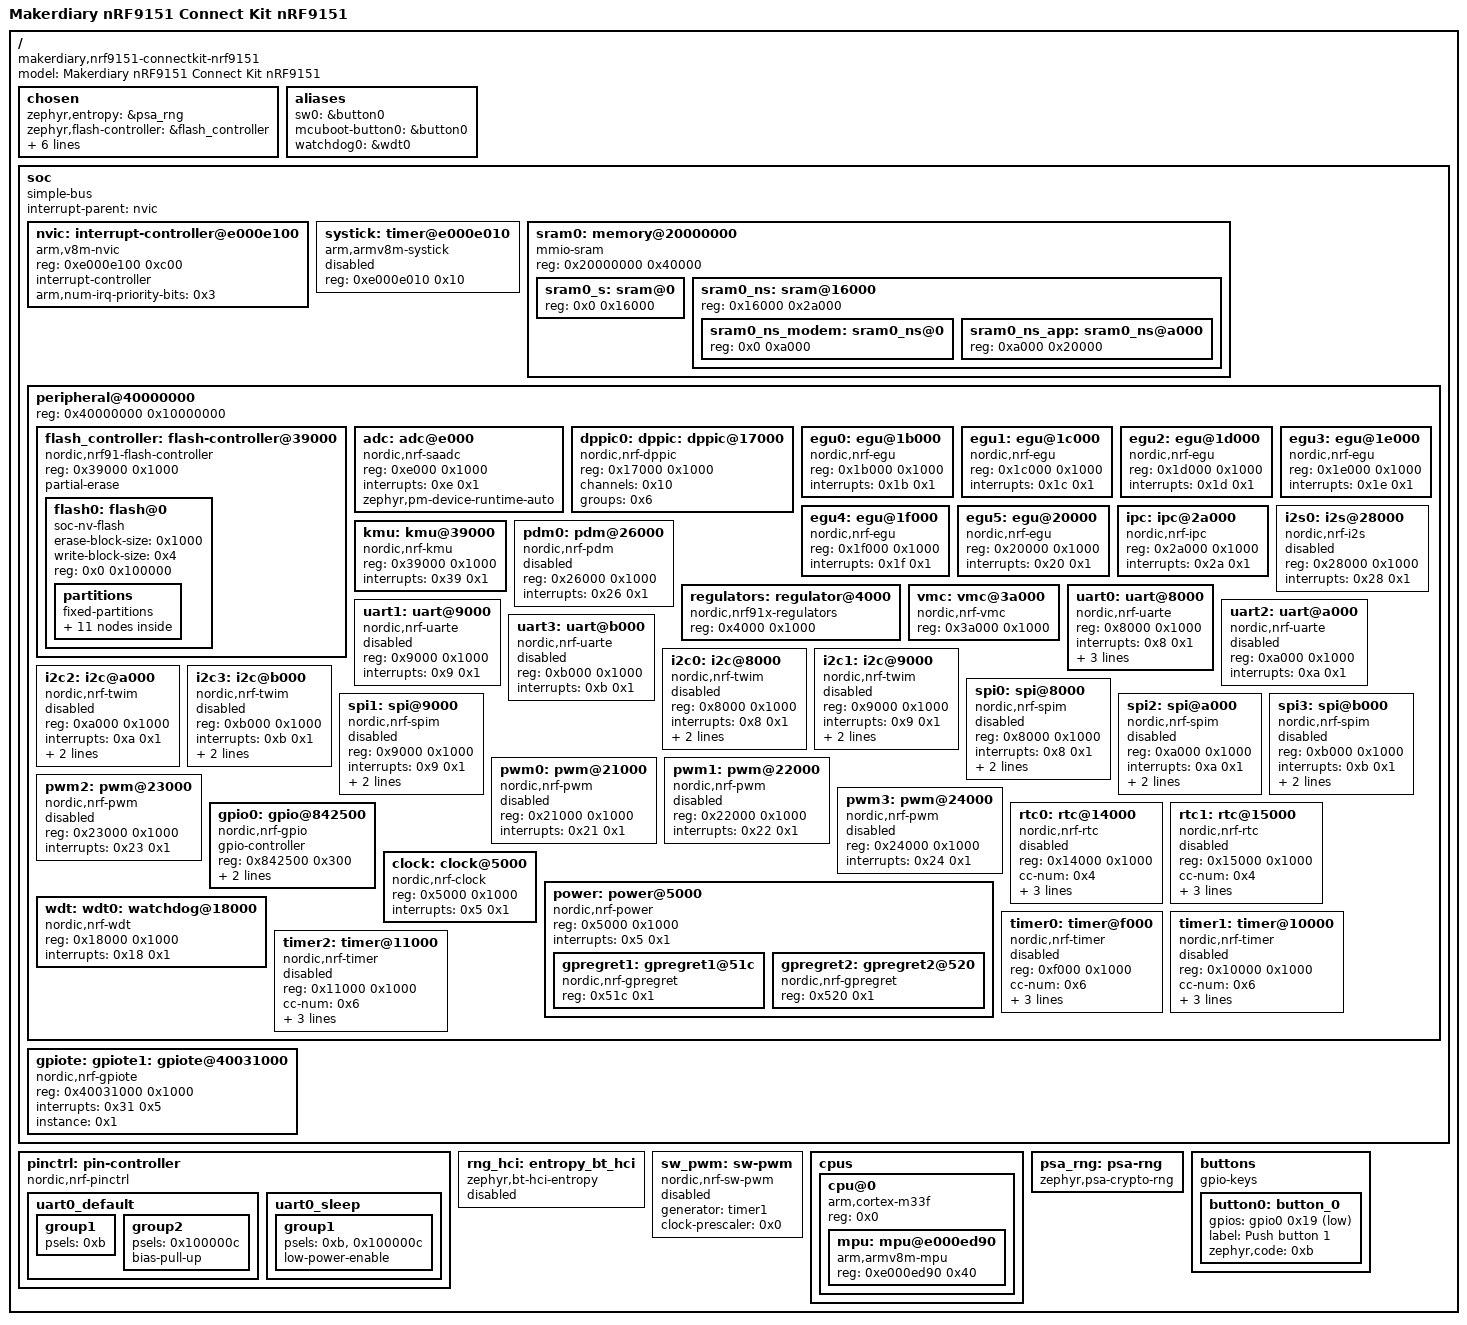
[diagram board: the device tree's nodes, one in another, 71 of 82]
/dts-v1/;

/* node '/' defined in zephyr/dts/common/skeleton.dtsi:9 */
/ {
	#address-cells = < 0x1 >;                             /* in zephyr/dts/common/skeleton.dtsi:10 */
	#size-cells = < 0x1 >;                                /* in zephyr/dts/common/skeleton.dtsi:11 */
	model = "Makerdiary nRF9151 Connect Kit nRF9151";     /* in ../../Documents/DECT_2020_GIT/dect_shell/boards/nrf9151_connectkit/nrf9151_connectkit_nrf9151_common.dtsi:10 */
	compatible = "makerdiary,nrf9151-connectkit-nrf9151"; /* in ../../Documents/DECT_2020_GIT/dect_shell/boards/nrf9151_connectkit/nrf9151_connectkit_nrf9151_common.dtsi:11 */

	/* node '/chosen' defined in zephyr/dts/common/skeleton.dtsi:13 */
	chosen {
		zephyr,entropy = &psa_rng;                   /* in zephyr/dts/arm/nordic/nrf91_ns.dtsi:31 */
		zephyr,flash-controller = &flash_controller; /* in zephyr/dts/arm/nordic/nrf91_ns.dtsi:32 */
		zephyr,console = &uart0;                     /* in ../../Documents/DECT_2020_GIT/dect_shell/boards/nrf9151_connectkit/nrf9151_connectkit_nrf9151_common.dtsi:14 */
		zephyr,shell-uart = &uart0;                  /* in ../../Documents/DECT_2020_GIT/dect_shell/boards/nrf9151_connectkit/nrf9151_connectkit_nrf9151_common.dtsi:15 */
		zephyr,uart-mcumgr = &uart0;                 /* in ../../Documents/DECT_2020_GIT/dect_shell/boards/nrf9151_connectkit/nrf9151_connectkit_nrf9151_common.dtsi:16 */
		zephyr,flash = &flash0;                      /* in ../../Documents/DECT_2020_GIT/dect_shell/boards/nrf9151_connectkit/nrf9151_connectkit_nrf9151_ns.dts:13 */
		zephyr,sram = &sram0_ns_app;                 /* in ../../Documents/DECT_2020_GIT/dect_shell/boards/nrf9151_connectkit/nrf9151_connectkit_nrf9151_ns.dts:14 */
		zephyr,code-partition = &slot0_ns_partition; /* in ../../Documents/DECT_2020_GIT/dect_shell/boards/nrf9151_connectkit/nrf9151_connectkit_nrf9151_ns.dts:15 */
	};

	/* node '/aliases' defined in zephyr/dts/common/skeleton.dtsi:15 */
	aliases {
		sw0 = &button0;             /* in ../../Documents/DECT_2020_GIT/dect_shell/boards/nrf9151_connectkit/nrf9151_connectkit_nrf9151_common.dtsi:30 */
		mcuboot-button0 = &button0; /* in ../../Documents/DECT_2020_GIT/dect_shell/boards/nrf9151_connectkit/nrf9151_connectkit_nrf9151_common.dtsi:31 */
		watchdog0 = &wdt0;          /* in ../../Documents/DECT_2020_GIT/dect_shell/boards/nrf9151_connectkit/nrf9151_connectkit_nrf9151_common.dtsi:32 */
	};

	/* node '/soc' defined in zephyr/dts/arm/armv8-m.dtsi:6 */
	soc {
		#address-cells = < 0x1 >;     /* in zephyr/dts/arm/armv8-m.dtsi:7 */
		#size-cells = < 0x1 >;        /* in zephyr/dts/arm/armv8-m.dtsi:8 */
		interrupt-parent = < &nvic >; /* in zephyr/dts/arm/armv8-m.dtsi:10 */
		ranges;                       /* in zephyr/dts/arm/armv8-m.dtsi:11 */
		compatible = "simple-bus";    /* in zephyr/dts/arm/nordic/nrf9151_ns_laca.dtsi:21 */

		/* node '/soc/interrupt-controller@e000e100' defined in zephyr/dts/arm/armv8-m.dtsi:13 */
		nvic: interrupt-controller@e000e100 {
			#address-cells = < 0x1 >;            /* in zephyr/dts/arm/armv8-m.dtsi:14 */
			compatible = "arm,v8m-nvic";         /* in zephyr/dts/arm/armv8-m.dtsi:15 */
			reg = < 0xe000e100 0xc00 >;          /* in zephyr/dts/arm/armv8-m.dtsi:16 */
			interrupt-controller;                /* in zephyr/dts/arm/armv8-m.dtsi:17 */
			#interrupt-cells = < 0x2 >;          /* in zephyr/dts/arm/armv8-m.dtsi:18 */
			arm,num-irq-priority-bits = < 0x3 >; /* in zephyr/dts/arm/nordic/nrf91_ns.dtsi:73 */
			phandle = < 0x1 >;                   /* in zephyr/dts/arm/armv8-m.dtsi:10 */
		};

		/* node '/soc/timer@e000e010' defined in zephyr/dts/arm/armv8-m.dtsi:21 */
		systick: timer@e000e010 {
			compatible = "arm,armv8m-systick"; /* in zephyr/dts/arm/armv8-m.dtsi:22 */
			reg = < 0xe000e010 0x10 >;         /* in zephyr/dts/arm/armv8-m.dtsi:23 */
			status = "disabled";               /* in zephyr/dts/arm/nordic/nrf91_ns.dtsi:78 */
		};

		/* node '/soc/memory@20000000' defined in zephyr/dts/arm/nordic/nrf91_ns.dtsi:36 */
		sram0: memory@20000000 {
			compatible = "mmio-sram";            /* in zephyr/dts/arm/nordic/nrf91_ns.dtsi:37 */
			#address-cells = < 0x1 >;            /* in zephyr/dts/arm/nordic/nrf91_ns.dtsi:38 */
			#size-cells = < 0x1 >;               /* in zephyr/dts/arm/nordic/nrf91_ns.dtsi:39 */
			reg = < 0x20000000 0x40000 >;        /* in zephyr/dts/arm/nordic/nrf9151_ns_laca.dtsi:15 */
			ranges = < 0x0 0x20000000 0x40000 >; /* in zephyr/dts/arm/nordic/nrf9151_ns_laca.dtsi:16 */

			/* node '/soc/memory@20000000/sram@0' defined in zephyr/dts/vendor/nordic/nrf91xx_partition.dtsi:107 */
			sram0_s: sram@0 {
				reg = < 0x0 0x16000 >; /* in zephyr/dts/vendor/nordic/nrf91xx_partition.dtsi:109 */
			};

			/* node '/soc/memory@20000000/sram@16000' defined in zephyr/dts/vendor/nordic/nrf91xx_partition.dtsi:112 */
			sram0_ns: sram@16000 {
				reg = < 0x16000 0x2a000 >;        /* in zephyr/dts/vendor/nordic/nrf91xx_partition.dtsi:114 */
				#address-cells = < 0x1 >;         /* in zephyr/dts/vendor/nordic/nrf91xx_partition.dtsi:115 */
				#size-cells = < 0x1 >;            /* in zephyr/dts/vendor/nordic/nrf91xx_partition.dtsi:116 */
				ranges = < 0x0 0x16000 0x2a000 >; /* in zephyr/dts/vendor/nordic/nrf91xx_partition.dtsi:117 */

				/* node '/soc/memory@20000000/sram@16000/sram0_ns@0' defined in zephyr/dts/vendor/nordic/nrf91xx_partition.dtsi:119 */
				sram0_ns_modem: sram0_ns@0 {
					reg = < 0x0 0xa000 >; /* in zephyr/dts/vendor/nordic/nrf91xx_partition.dtsi:121 */
				};

				/* node '/soc/memory@20000000/sram@16000/sram0_ns@a000' defined in zephyr/dts/vendor/nordic/nrf91xx_partition.dtsi:124 */
				sram0_ns_app: sram0_ns@a000 {
					reg = < 0xa000 0x20000 >; /* in zephyr/dts/vendor/nordic/nrf91xx_partition.dtsi:126 */
				};
			};
		};

		/* node '/soc/peripheral@40000000' defined in zephyr/dts/arm/nordic/nrf91_ns.dtsi:42 */
		peripheral@40000000 {
			#address-cells = < 0x1 >;               /* in zephyr/dts/arm/nordic/nrf91_ns.dtsi:43 */
			#size-cells = < 0x1 >;                  /* in zephyr/dts/arm/nordic/nrf91_ns.dtsi:44 */
			reg = < 0x40000000 0x10000000 >;        /* in zephyr/dts/arm/nordic/nrf91_ns.dtsi:45 */
			ranges = < 0x0 0x40000000 0x10000000 >; /* in zephyr/dts/arm/nordic/nrf91_ns.dtsi:46 */

			/* node '/soc/peripheral@40000000/flash-controller@39000' defined in zephyr/dts/arm/nordic/nrf91_peripherals.dtsi:7 */
			flash_controller: flash-controller@39000 {
				compatible = "nordic,nrf91-flash-controller"; /* in zephyr/dts/arm/nordic/nrf91_peripherals.dtsi:8 */
				reg = < 0x39000 0x1000 >;                     /* in zephyr/dts/arm/nordic/nrf91_peripherals.dtsi:9 */
				partial-erase;                                /* in zephyr/dts/arm/nordic/nrf91_peripherals.dtsi:10 */
				#address-cells = < 0x1 >;                     /* in zephyr/dts/arm/nordic/nrf91_peripherals.dtsi:12 */
				#size-cells = < 0x1 >;                        /* in zephyr/dts/arm/nordic/nrf91_peripherals.dtsi:13 */

				/* node '/soc/peripheral@40000000/flash-controller@39000/flash@0' defined in zephyr/dts/arm/nordic/nrf91_peripherals.dtsi:15 */
				flash0: flash@0 {
					compatible = "soc-nv-flash";   /* in zephyr/dts/arm/nordic/nrf91_peripherals.dtsi:16 */
					erase-block-size = < 0x1000 >; /* in zephyr/dts/arm/nordic/nrf91_peripherals.dtsi:17 */
					write-block-size = < 0x4 >;    /* in zephyr/dts/arm/nordic/nrf91_peripherals.dtsi:18 */
					reg = < 0x0 0x100000 >;        /* in zephyr/dts/arm/nordic/nrf9151_ns_laca.dtsi:11 */

					/* node '/soc/peripheral@40000000/flash-controller@39000/flash@0/partitions' defined in zephyr/dts/vendor/nordic/nrf91xx_partition.dtsi:27 */
					partitions {
						compatible = "fixed-partitions"; /* in zephyr/dts/vendor/nordic/nrf91xx_partition.dtsi:28 */
						#address-cells = < 0x1 >;        /* in zephyr/dts/vendor/nordic/nrf91xx_partition.dtsi:29 */
						#size-cells = < 0x1 >;           /* in zephyr/dts/vendor/nordic/nrf91xx_partition.dtsi:30 */

						/* node '/soc/peripheral@40000000/flash-controller@39000/flash@0/partitions/partition@0' defined in zephyr/dts/vendor/nordic/nrf91xx_partition.dtsi:32 */
						boot_partition: partition@0 {
							label = "mcuboot";     /* in zephyr/dts/vendor/nordic/nrf91xx_partition.dtsi:33 */
							reg = < 0x0 0x10000 >; /* in zephyr/dts/vendor/nordic/nrf91xx_partition.dtsi:34 */
						};

						/* node '/soc/peripheral@40000000/flash-controller@39000/flash@0/partitions/partition@10000' defined in zephyr/dts/vendor/nordic/nrf91xx_partition.dtsi:37 */
						slot0_partition: partition@10000 {
							compatible = "fixed-subpartitions"; /* in zephyr/dts/vendor/nordic/nrf91xx_partition.dtsi:38 */
							label = "image-0";                  /* in zephyr/dts/vendor/nordic/nrf91xx_partition.dtsi:39 */
							reg = < 0x10000 0x70000 >;          /* in zephyr/dts/vendor/nordic/nrf91xx_partition.dtsi:40 */
							ranges = < 0x0 0x10000 0x70000 >;   /* in zephyr/dts/vendor/nordic/nrf91xx_partition.dtsi:41 */
							#address-cells = < 0x1 >;           /* in zephyr/dts/vendor/nordic/nrf91xx_partition.dtsi:42 */
							#size-cells = < 0x1 >;              /* in zephyr/dts/vendor/nordic/nrf91xx_partition.dtsi:43 */

							/* node '/soc/peripheral@40000000/flash-controller@39000/flash@0/partitions/partition@10000/partition@0' defined in zephyr/dts/vendor/nordic/nrf91xx_partition.dtsi:45 */
							slot0_s_partition: partition@0 {
								label = "image-0-secure"; /* in zephyr/dts/vendor/nordic/nrf91xx_partition.dtsi:46 */
								reg = < 0x0 0x40000 >;    /* in zephyr/dts/vendor/nordic/nrf91xx_partition.dtsi:47 */
							};

							/* node '/soc/peripheral@40000000/flash-controller@39000/flash@0/partitions/partition@10000/partition@40000' defined in zephyr/dts/vendor/nordic/nrf91xx_partition.dtsi:50 */
							slot0_ns_partition: partition@40000 {
								label = "image-0-nonsecure"; /* in zephyr/dts/vendor/nordic/nrf91xx_partition.dtsi:51 */
								reg = < 0x40000 0x30000 >;   /* in zephyr/dts/vendor/nordic/nrf91xx_partition.dtsi:52 */
							};
						};

						/* node '/soc/peripheral@40000000/flash-controller@39000/flash@0/partitions/partition@80000' defined in zephyr/dts/vendor/nordic/nrf91xx_partition.dtsi:56 */
						slot1_partition: partition@80000 {
							compatible = "fixed-subpartitions"; /* in zephyr/dts/vendor/nordic/nrf91xx_partition.dtsi:57 */
							label = "image-1";                  /* in zephyr/dts/vendor/nordic/nrf91xx_partition.dtsi:58 */
							reg = < 0x80000 0x70000 >;          /* in zephyr/dts/vendor/nordic/nrf91xx_partition.dtsi:59 */
							ranges = < 0x0 0x80000 0x70000 >;   /* in zephyr/dts/vendor/nordic/nrf91xx_partition.dtsi:60 */
							#address-cells = < 0x1 >;           /* in zephyr/dts/vendor/nordic/nrf91xx_partition.dtsi:61 */
							#size-cells = < 0x1 >;              /* in zephyr/dts/vendor/nordic/nrf91xx_partition.dtsi:62 */

							/* node '/soc/peripheral@40000000/flash-controller@39000/flash@0/partitions/partition@80000/partition@0' defined in zephyr/dts/vendor/nordic/nrf91xx_partition.dtsi:64 */
							slot1_s_partition: partition@0 {
								label = "image-1-secure"; /* in zephyr/dts/vendor/nordic/nrf91xx_partition.dtsi:65 */
								reg = < 0x0 0x40000 >;    /* in zephyr/dts/vendor/nordic/nrf91xx_partition.dtsi:66 */
							};

							/* node '/soc/peripheral@40000000/flash-controller@39000/flash@0/partitions/partition@80000/partition@40000' defined in zephyr/dts/vendor/nordic/nrf91xx_partition.dtsi:69 */
							slot1_ns_partition: partition@40000 {
								label = "image-1-nonsecure"; /* in zephyr/dts/vendor/nordic/nrf91xx_partition.dtsi:70 */
								reg = < 0x40000 0x30000 >;   /* in zephyr/dts/vendor/nordic/nrf91xx_partition.dtsi:71 */
							};
						};

						/* node '/soc/peripheral@40000000/flash-controller@39000/flash@0/partitions/partition@f0000' defined in zephyr/dts/vendor/nordic/nrf91xx_partition.dtsi:75 */
						tfm_ps_partition: partition@f0000 {
							label = "tfm-ps";         /* in zephyr/dts/vendor/nordic/nrf91xx_partition.dtsi:76 */
							reg = < 0xf0000 0x4000 >; /* in zephyr/dts/vendor/nordic/nrf91xx_partition.dtsi:77 */
						};

						/* node '/soc/peripheral@40000000/flash-controller@39000/flash@0/partitions/partition@f4000' defined in zephyr/dts/vendor/nordic/nrf91xx_partition.dtsi:80 */
						tfm_its_partition: partition@f4000 {
							label = "tfm-its";        /* in zephyr/dts/vendor/nordic/nrf91xx_partition.dtsi:81 */
							reg = < 0xf4000 0x2000 >; /* in zephyr/dts/vendor/nordic/nrf91xx_partition.dtsi:82 */
						};

						/* node '/soc/peripheral@40000000/flash-controller@39000/flash@0/partitions/partition@f6000' defined in zephyr/dts/vendor/nordic/nrf91xx_partition.dtsi:85 */
						tfm_otp_partition: partition@f6000 {
							label = "tfm-otp";        /* in zephyr/dts/vendor/nordic/nrf91xx_partition.dtsi:86 */
							reg = < 0xf6000 0x2000 >; /* in zephyr/dts/vendor/nordic/nrf91xx_partition.dtsi:87 */
						};

						/* node '/soc/peripheral@40000000/flash-controller@39000/flash@0/partitions/partition@f8000' defined in zephyr/dts/vendor/nordic/nrf91xx_partition.dtsi:90 */
						storage_partition: partition@f8000 {
							label = "storage";        /* in zephyr/dts/vendor/nordic/nrf91xx_partition.dtsi:91 */
							reg = < 0xf8000 0x8000 >; /* in zephyr/dts/vendor/nordic/nrf91xx_partition.dtsi:92 */
						};
					};
				};
			};

			/* node '/soc/peripheral@40000000/adc@e000' defined in zephyr/dts/arm/nordic/nrf91_peripherals.dtsi:22 */
			adc: adc@e000 {
				compatible = "nordic,nrf-saadc"; /* in zephyr/dts/arm/nordic/nrf91_peripherals.dtsi:23 */
				reg = < 0xe000 0x1000 >;         /* in zephyr/dts/arm/nordic/nrf91_peripherals.dtsi:24 */
				interrupts = < 0xe 0x1 >;        /* in zephyr/dts/arm/nordic/nrf91_peripherals.dtsi:25 */
				#io-channel-cells = < 0x1 >;     /* in zephyr/dts/arm/nordic/nrf91_peripherals.dtsi:27 */
				zephyr,pm-device-runtime-auto;   /* in zephyr/dts/arm/nordic/nrf91_peripherals.dtsi:28 */
				status = "okay";                 /* in ../../Documents/DECT_2020_GIT/dect_shell/boards/nrf9151_connectkit/nrf9151_connectkit_nrf9151_common.dtsi:37 */
			};

			/* node '/soc/peripheral@40000000/dppic@17000' defined in zephyr/dts/arm/nordic/nrf91_peripherals.dtsi:31 */
			dppic0: dppic: dppic@17000 {
				compatible = "nordic,nrf-dppic"; /* in zephyr/dts/arm/nordic/nrf91_peripherals.dtsi:32 */
				reg = < 0x17000 0x1000 >;        /* in zephyr/dts/arm/nordic/nrf91_peripherals.dtsi:33 */
				status = "okay";                 /* in zephyr/dts/arm/nordic/nrf91_peripherals.dtsi:34 */
				channels = < 0x10 >;             /* in zephyr/dts/arm/nordic/nrf91_peripherals.dtsi:35 */
				groups = < 0x6 >;                /* in zephyr/dts/arm/nordic/nrf91_peripherals.dtsi:36 */
			};

			/* node '/soc/peripheral@40000000/egu@1b000' defined in zephyr/dts/arm/nordic/nrf91_peripherals.dtsi:39 */
			egu0: egu@1b000 {
				compatible = "nordic,nrf-egu"; /* in zephyr/dts/arm/nordic/nrf91_peripherals.dtsi:40 */
				reg = < 0x1b000 0x1000 >;      /* in zephyr/dts/arm/nordic/nrf91_peripherals.dtsi:41 */
				interrupts = < 0x1b 0x1 >;     /* in zephyr/dts/arm/nordic/nrf91_peripherals.dtsi:42 */
				status = "okay";               /* in zephyr/dts/arm/nordic/nrf91_peripherals.dtsi:43 */
			};

			/* node '/soc/peripheral@40000000/egu@1c000' defined in zephyr/dts/arm/nordic/nrf91_peripherals.dtsi:46 */
			egu1: egu@1c000 {
				compatible = "nordic,nrf-egu"; /* in zephyr/dts/arm/nordic/nrf91_peripherals.dtsi:47 */
				reg = < 0x1c000 0x1000 >;      /* in zephyr/dts/arm/nordic/nrf91_peripherals.dtsi:48 */
				interrupts = < 0x1c 0x1 >;     /* in zephyr/dts/arm/nordic/nrf91_peripherals.dtsi:49 */
				status = "okay";               /* in zephyr/dts/arm/nordic/nrf91_peripherals.dtsi:50 */
			};

			/* node '/soc/peripheral@40000000/egu@1d000' defined in zephyr/dts/arm/nordic/nrf91_peripherals.dtsi:53 */
			egu2: egu@1d000 {
				compatible = "nordic,nrf-egu"; /* in zephyr/dts/arm/nordic/nrf91_peripherals.dtsi:54 */
				reg = < 0x1d000 0x1000 >;      /* in zephyr/dts/arm/nordic/nrf91_peripherals.dtsi:55 */
				interrupts = < 0x1d 0x1 >;     /* in zephyr/dts/arm/nordic/nrf91_peripherals.dtsi:56 */
				status = "okay";               /* in zephyr/dts/arm/nordic/nrf91_peripherals.dtsi:57 */
			};

			/* node '/soc/peripheral@40000000/egu@1e000' defined in zephyr/dts/arm/nordic/nrf91_peripherals.dtsi:60 */
			egu3: egu@1e000 {
				compatible = "nordic,nrf-egu"; /* in zephyr/dts/arm/nordic/nrf91_peripherals.dtsi:61 */
				reg = < 0x1e000 0x1000 >;      /* in zephyr/dts/arm/nordic/nrf91_peripherals.dtsi:62 */
				interrupts = < 0x1e 0x1 >;     /* in zephyr/dts/arm/nordic/nrf91_peripherals.dtsi:63 */
				status = "okay";               /* in zephyr/dts/arm/nordic/nrf91_peripherals.dtsi:64 */
			};

			/* node '/soc/peripheral@40000000/egu@1f000' defined in zephyr/dts/arm/nordic/nrf91_peripherals.dtsi:67 */
			egu4: egu@1f000 {
				compatible = "nordic,nrf-egu"; /* in zephyr/dts/arm/nordic/nrf91_peripherals.dtsi:68 */
				reg = < 0x1f000 0x1000 >;      /* in zephyr/dts/arm/nordic/nrf91_peripherals.dtsi:69 */
				interrupts = < 0x1f 0x1 >;     /* in zephyr/dts/arm/nordic/nrf91_peripherals.dtsi:70 */
				status = "okay";               /* in zephyr/dts/arm/nordic/nrf91_peripherals.dtsi:71 */
			};

			/* node '/soc/peripheral@40000000/egu@20000' defined in zephyr/dts/arm/nordic/nrf91_peripherals.dtsi:74 */
			egu5: egu@20000 {
				compatible = "nordic,nrf-egu"; /* in zephyr/dts/arm/nordic/nrf91_peripherals.dtsi:75 */
				reg = < 0x20000 0x1000 >;      /* in zephyr/dts/arm/nordic/nrf91_peripherals.dtsi:76 */
				interrupts = < 0x20 0x1 >;     /* in zephyr/dts/arm/nordic/nrf91_peripherals.dtsi:77 */
				status = "okay";               /* in zephyr/dts/arm/nordic/nrf91_peripherals.dtsi:78 */
			};

			/* node '/soc/peripheral@40000000/ipc@2a000' defined in zephyr/dts/arm/nordic/nrf91_peripherals.dtsi:81 */
			ipc: ipc@2a000 {
				compatible = "nordic,nrf-ipc"; /* in zephyr/dts/arm/nordic/nrf91_peripherals.dtsi:82 */
				reg = < 0x2a000 0x1000 >;      /* in zephyr/dts/arm/nordic/nrf91_peripherals.dtsi:83 */
				interrupts = < 0x2a 0x1 >;     /* in zephyr/dts/arm/nordic/nrf91_peripherals.dtsi:84 */
				status = "okay";               /* in zephyr/dts/arm/nordic/nrf91_peripherals.dtsi:85 */
			};

			/* node '/soc/peripheral@40000000/i2s@28000' defined in zephyr/dts/arm/nordic/nrf91_peripherals.dtsi:88 */
			i2s0: i2s@28000 {
				compatible = "nordic,nrf-i2s"; /* in zephyr/dts/arm/nordic/nrf91_peripherals.dtsi:89 */
				#address-cells = < 0x1 >;      /* in zephyr/dts/arm/nordic/nrf91_peripherals.dtsi:90 */
				#size-cells = < 0x0 >;         /* in zephyr/dts/arm/nordic/nrf91_peripherals.dtsi:91 */
				reg = < 0x28000 0x1000 >;      /* in zephyr/dts/arm/nordic/nrf91_peripherals.dtsi:92 */
				interrupts = < 0x28 0x1 >;     /* in zephyr/dts/arm/nordic/nrf91_peripherals.dtsi:93 */
				status = "disabled";           /* in zephyr/dts/arm/nordic/nrf91_peripherals.dtsi:94 */
			};

			/* node '/soc/peripheral@40000000/kmu@39000' defined in zephyr/dts/arm/nordic/nrf91_peripherals.dtsi:97 */
			kmu: kmu@39000 {
				compatible = "nordic,nrf-kmu"; /* in zephyr/dts/arm/nordic/nrf91_peripherals.dtsi:98 */
				reg = < 0x39000 0x1000 >;      /* in zephyr/dts/arm/nordic/nrf91_peripherals.dtsi:99 */
				interrupts = < 0x39 0x1 >;     /* in zephyr/dts/arm/nordic/nrf91_peripherals.dtsi:100 */
				status = "okay";               /* in zephyr/dts/arm/nordic/nrf91_peripherals.dtsi:101 */
			};

			/* node '/soc/peripheral@40000000/pdm@26000' defined in zephyr/dts/arm/nordic/nrf91_peripherals.dtsi:104 */
			pdm0: pdm@26000 {
				compatible = "nordic,nrf-pdm"; /* in zephyr/dts/arm/nordic/nrf91_peripherals.dtsi:105 */
				reg = < 0x26000 0x1000 >;      /* in zephyr/dts/arm/nordic/nrf91_peripherals.dtsi:106 */
				interrupts = < 0x26 0x1 >;     /* in zephyr/dts/arm/nordic/nrf91_peripherals.dtsi:107 */
				status = "disabled";           /* in zephyr/dts/arm/nordic/nrf91_peripherals.dtsi:108 */
			};

			/* node '/soc/peripheral@40000000/regulator@4000' defined in zephyr/dts/arm/nordic/nrf91_peripherals.dtsi:111 */
			regulators: regulator@4000 {
				compatible = "nordic,nrf91x-regulators"; /* in zephyr/dts/arm/nordic/nrf91_peripherals.dtsi:112 */
				reg = < 0x4000 0x1000 >;                 /* in zephyr/dts/arm/nordic/nrf91_peripherals.dtsi:113 */
				status = "okay";                         /* in zephyr/dts/arm/nordic/nrf91_peripherals.dtsi:114 */
			};

			/* node '/soc/peripheral@40000000/vmc@3a000' defined in zephyr/dts/arm/nordic/nrf91_peripherals.dtsi:117 */
			vmc: vmc@3a000 {
				compatible = "nordic,nrf-vmc"; /* in zephyr/dts/arm/nordic/nrf91_peripherals.dtsi:118 */
				reg = < 0x3a000 0x1000 >;      /* in zephyr/dts/arm/nordic/nrf91_peripherals.dtsi:119 */
				status = "okay";               /* in zephyr/dts/arm/nordic/nrf91_peripherals.dtsi:120 */
			};

			/* node '/soc/peripheral@40000000/uart@8000' defined in zephyr/dts/arm/nordic/nrf91_peripherals.dtsi:123 */
			uart0: uart@8000 {
				compatible = "nordic,nrf-uarte"; /* in zephyr/dts/arm/nordic/nrf91_peripherals.dtsi:124 */
				reg = < 0x8000 0x1000 >;         /* in zephyr/dts/arm/nordic/nrf91_peripherals.dtsi:125 */
				interrupts = < 0x8 0x1 >;        /* in zephyr/dts/arm/nordic/nrf91_peripherals.dtsi:126 */
				status = "okay";                 /* in ../../Documents/DECT_2020_GIT/dect_shell/boards/nrf9151_connectkit/nrf9151_connectkit_nrf9151_common.dtsi:49 */
				current-speed = < 0x1c200 >;     /* in ../../Documents/DECT_2020_GIT/dect_shell/boards/nrf9151_connectkit/nrf9151_connectkit_nrf9151_common.dtsi:50 */
				pinctrl-0 = < &uart0_default >;  /* in ../../Documents/DECT_2020_GIT/dect_shell/boards/nrf9151_connectkit/nrf9151_connectkit_nrf9151_common.dtsi:51 */
				pinctrl-1 = < &uart0_sleep >;    /* in ../../Documents/DECT_2020_GIT/dect_shell/boards/nrf9151_connectkit/nrf9151_connectkit_nrf9151_common.dtsi:52 */
				pinctrl-names = "default",
				                "sleep";         /* in ../../Documents/DECT_2020_GIT/dect_shell/boards/nrf9151_connectkit/nrf9151_connectkit_nrf9151_common.dtsi:53 */
			};

			/* node '/soc/peripheral@40000000/uart@9000' defined in zephyr/dts/arm/nordic/nrf91_peripherals.dtsi:130 */
			uart1: uart@9000 {
				compatible = "nordic,nrf-uarte"; /* in zephyr/dts/arm/nordic/nrf91_peripherals.dtsi:131 */
				reg = < 0x9000 0x1000 >;         /* in zephyr/dts/arm/nordic/nrf91_peripherals.dtsi:132 */
				interrupts = < 0x9 0x1 >;        /* in zephyr/dts/arm/nordic/nrf91_peripherals.dtsi:133 */
				status = "disabled";             /* in zephyr/dts/arm/nordic/nrf91_peripherals.dtsi:134 */
			};

			/* node '/soc/peripheral@40000000/uart@a000' defined in zephyr/dts/arm/nordic/nrf91_peripherals.dtsi:137 */
			uart2: uart@a000 {
				compatible = "nordic,nrf-uarte"; /* in zephyr/dts/arm/nordic/nrf91_peripherals.dtsi:138 */
				reg = < 0xa000 0x1000 >;         /* in zephyr/dts/arm/nordic/nrf91_peripherals.dtsi:139 */
				interrupts = < 0xa 0x1 >;        /* in zephyr/dts/arm/nordic/nrf91_peripherals.dtsi:140 */
				status = "disabled";             /* in zephyr/dts/arm/nordic/nrf91_peripherals.dtsi:141 */
			};

			/* node '/soc/peripheral@40000000/uart@b000' defined in zephyr/dts/arm/nordic/nrf91_peripherals.dtsi:144 */
			uart3: uart@b000 {
				compatible = "nordic,nrf-uarte"; /* in zephyr/dts/arm/nordic/nrf91_peripherals.dtsi:145 */
				reg = < 0xb000 0x1000 >;         /* in zephyr/dts/arm/nordic/nrf91_peripherals.dtsi:146 */
				interrupts = < 0xb 0x1 >;        /* in zephyr/dts/arm/nordic/nrf91_peripherals.dtsi:147 */
				status = "disabled";             /* in zephyr/dts/arm/nordic/nrf91_peripherals.dtsi:148 */
			};

			/* node '/soc/peripheral@40000000/i2c@8000' defined in zephyr/dts/arm/nordic/nrf91_peripherals.dtsi:151 */
			i2c0: i2c@8000 {
				compatible = "nordic,nrf-twim"; /* in zephyr/dts/arm/nordic/nrf91_peripherals.dtsi:157 */
				#address-cells = < 0x1 >;       /* in zephyr/dts/arm/nordic/nrf91_peripherals.dtsi:158 */
				#size-cells = < 0x0 >;          /* in zephyr/dts/arm/nordic/nrf91_peripherals.dtsi:159 */
				reg = < 0x8000 0x1000 >;        /* in zephyr/dts/arm/nordic/nrf91_peripherals.dtsi:160 */
				interrupts = < 0x8 0x1 >;       /* in zephyr/dts/arm/nordic/nrf91_peripherals.dtsi:161 */
				easydma-maxcnt-bits = < 0xd >;  /* in zephyr/dts/arm/nordic/nrf91_peripherals.dtsi:162 */
				status = "disabled";            /* in zephyr/dts/arm/nordic/nrf91_peripherals.dtsi:163 */
				zephyr,pm-device-runtime-auto;  /* in zephyr/dts/arm/nordic/nrf91_peripherals.dtsi:164 */
			};

			/* node '/soc/peripheral@40000000/i2c@9000' defined in zephyr/dts/arm/nordic/nrf91_peripherals.dtsi:167 */
			i2c1: i2c@9000 {
				compatible = "nordic,nrf-twim"; /* in zephyr/dts/arm/nordic/nrf91_peripherals.dtsi:173 */
				#address-cells = < 0x1 >;       /* in zephyr/dts/arm/nordic/nrf91_peripherals.dtsi:174 */
				#size-cells = < 0x0 >;          /* in zephyr/dts/arm/nordic/nrf91_peripherals.dtsi:175 */
				reg = < 0x9000 0x1000 >;        /* in zephyr/dts/arm/nordic/nrf91_peripherals.dtsi:176 */
				interrupts = < 0x9 0x1 >;       /* in zephyr/dts/arm/nordic/nrf91_peripherals.dtsi:177 */
				easydma-maxcnt-bits = < 0xd >;  /* in zephyr/dts/arm/nordic/nrf91_peripherals.dtsi:178 */
				status = "disabled";            /* in zephyr/dts/arm/nordic/nrf91_peripherals.dtsi:179 */
				zephyr,pm-device-runtime-auto;  /* in zephyr/dts/arm/nordic/nrf91_peripherals.dtsi:180 */
			};

			/* node '/soc/peripheral@40000000/i2c@a000' defined in zephyr/dts/arm/nordic/nrf91_peripherals.dtsi:183 */
			i2c2: i2c@a000 {
				compatible = "nordic,nrf-twim"; /* in zephyr/dts/arm/nordic/nrf91_peripherals.dtsi:189 */
				#address-cells = < 0x1 >;       /* in zephyr/dts/arm/nordic/nrf91_peripherals.dtsi:190 */
				#size-cells = < 0x0 >;          /* in zephyr/dts/arm/nordic/nrf91_peripherals.dtsi:191 */
				reg = < 0xa000 0x1000 >;        /* in zephyr/dts/arm/nordic/nrf91_peripherals.dtsi:192 */
				interrupts = < 0xa 0x1 >;       /* in zephyr/dts/arm/nordic/nrf91_peripherals.dtsi:193 */
				easydma-maxcnt-bits = < 0xd >;  /* in zephyr/dts/arm/nordic/nrf91_peripherals.dtsi:194 */
				status = "disabled";            /* in zephyr/dts/arm/nordic/nrf91_peripherals.dtsi:195 */
				zephyr,pm-device-runtime-auto;  /* in zephyr/dts/arm/nordic/nrf91_peripherals.dtsi:196 */
			};

			/* node '/soc/peripheral@40000000/i2c@b000' defined in zephyr/dts/arm/nordic/nrf91_peripherals.dtsi:199 */
			i2c3: i2c@b000 {
				compatible = "nordic,nrf-twim"; /* in zephyr/dts/arm/nordic/nrf91_peripherals.dtsi:205 */
				#address-cells = < 0x1 >;       /* in zephyr/dts/arm/nordic/nrf91_peripherals.dtsi:206 */
				#size-cells = < 0x0 >;          /* in zephyr/dts/arm/nordic/nrf91_peripherals.dtsi:207 */
				reg = < 0xb000 0x1000 >;        /* in zephyr/dts/arm/nordic/nrf91_peripherals.dtsi:208 */
				interrupts = < 0xb 0x1 >;       /* in zephyr/dts/arm/nordic/nrf91_peripherals.dtsi:209 */
				easydma-maxcnt-bits = < 0xd >;  /* in zephyr/dts/arm/nordic/nrf91_peripherals.dtsi:210 */
				status = "disabled";            /* in zephyr/dts/arm/nordic/nrf91_peripherals.dtsi:211 */
				zephyr,pm-device-runtime-auto;  /* in zephyr/dts/arm/nordic/nrf91_peripherals.dtsi:212 */
			};

			/* node '/soc/peripheral@40000000/spi@8000' defined in zephyr/dts/arm/nordic/nrf91_peripherals.dtsi:215 */
			spi0: spi@8000 {
				compatible = "nordic,nrf-spim"; /* in zephyr/dts/arm/nordic/nrf91_peripherals.dtsi:221 */
				#address-cells = < 0x1 >;       /* in zephyr/dts/arm/nordic/nrf91_peripherals.dtsi:222 */
				#size-cells = < 0x0 >;          /* in zephyr/dts/arm/nordic/nrf91_peripherals.dtsi:223 */
				reg = < 0x8000 0x1000 >;        /* in zephyr/dts/arm/nordic/nrf91_peripherals.dtsi:224 */
				interrupts = < 0x8 0x1 >;       /* in zephyr/dts/arm/nordic/nrf91_peripherals.dtsi:225 */
				max-frequency = < 0x7a1200 >;   /* in zephyr/dts/arm/nordic/nrf91_peripherals.dtsi:226 */
				easydma-maxcnt-bits = < 0xd >;  /* in zephyr/dts/arm/nordic/nrf91_peripherals.dtsi:227 */
				status = "disabled";            /* in zephyr/dts/arm/nordic/nrf91_peripherals.dtsi:228 */
			};

			/* node '/soc/peripheral@40000000/spi@9000' defined in zephyr/dts/arm/nordic/nrf91_peripherals.dtsi:231 */
			spi1: spi@9000 {
				compatible = "nordic,nrf-spim"; /* in zephyr/dts/arm/nordic/nrf91_peripherals.dtsi:237 */
				#address-cells = < 0x1 >;       /* in zephyr/dts/arm/nordic/nrf91_peripherals.dtsi:238 */
				#size-cells = < 0x0 >;          /* in zephyr/dts/arm/nordic/nrf91_peripherals.dtsi:239 */
				reg = < 0x9000 0x1000 >;        /* in zephyr/dts/arm/nordic/nrf91_peripherals.dtsi:240 */
				interrupts = < 0x9 0x1 >;       /* in zephyr/dts/arm/nordic/nrf91_peripherals.dtsi:241 */
				max-frequency = < 0x7a1200 >;   /* in zephyr/dts/arm/nordic/nrf91_peripherals.dtsi:242 */
				easydma-maxcnt-bits = < 0xd >;  /* in zephyr/dts/arm/nordic/nrf91_peripherals.dtsi:243 */
				status = "disabled";            /* in zephyr/dts/arm/nordic/nrf91_peripherals.dtsi:244 */
			};

			/* node '/soc/peripheral@40000000/spi@a000' defined in zephyr/dts/arm/nordic/nrf91_peripherals.dtsi:247 */
			spi2: spi@a000 {
				compatible = "nordic,nrf-spim"; /* in zephyr/dts/arm/nordic/nrf91_peripherals.dtsi:253 */
				#address-cells = < 0x1 >;       /* in zephyr/dts/arm/nordic/nrf91_peripherals.dtsi:254 */
				#size-cells = < 0x0 >;          /* in zephyr/dts/arm/nordic/nrf91_peripherals.dtsi:255 */
				reg = < 0xa000 0x1000 >;        /* in zephyr/dts/arm/nordic/nrf91_peripherals.dtsi:256 */
				interrupts = < 0xa 0x1 >;       /* in zephyr/dts/arm/nordic/nrf91_peripherals.dtsi:257 */
				max-frequency = < 0x7a1200 >;   /* in zephyr/dts/arm/nordic/nrf91_peripherals.dtsi:258 */
				easydma-maxcnt-bits = < 0xd >;  /* in zephyr/dts/arm/nordic/nrf91_peripherals.dtsi:259 */
				status = "disabled";            /* in zephyr/dts/arm/nordic/nrf91_peripherals.dtsi:260 */
			};

			/* node '/soc/peripheral@40000000/spi@b000' defined in zephyr/dts/arm/nordic/nrf91_peripherals.dtsi:263 */
			spi3: spi@b000 {
				compatible = "nordic,nrf-spim"; /* in zephyr/dts/arm/nordic/nrf91_peripherals.dtsi:269 */
				#address-cells = < 0x1 >;       /* in zephyr/dts/arm/nordic/nrf91_peripherals.dtsi:270 */
				#size-cells = < 0x0 >;          /* in zephyr/dts/arm/nordic/nrf91_peripherals.dtsi:271 */
				reg = < 0xb000 0x1000 >;        /* in zephyr/dts/arm/nordic/nrf91_peripherals.dtsi:272 */
				interrupts = < 0xb 0x1 >;       /* in zephyr/dts/arm/nordic/nrf91_peripherals.dtsi:273 */
				max-frequency = < 0x7a1200 >;   /* in zephyr/dts/arm/nordic/nrf91_peripherals.dtsi:274 */
				easydma-maxcnt-bits = < 0xd >;  /* in zephyr/dts/arm/nordic/nrf91_peripherals.dtsi:275 */
				status = "disabled";            /* in zephyr/dts/arm/nordic/nrf91_peripherals.dtsi:276 */
			};

			/* node '/soc/peripheral@40000000/pwm@21000' defined in zephyr/dts/arm/nordic/nrf91_peripherals.dtsi:279 */
			pwm0: pwm@21000 {
				compatible = "nordic,nrf-pwm"; /* in zephyr/dts/arm/nordic/nrf91_peripherals.dtsi:280 */
				reg = < 0x21000 0x1000 >;      /* in zephyr/dts/arm/nordic/nrf91_peripherals.dtsi:281 */
				interrupts = < 0x21 0x1 >;     /* in zephyr/dts/arm/nordic/nrf91_peripherals.dtsi:282 */
				status = "disabled";           /* in zephyr/dts/arm/nordic/nrf91_peripherals.dtsi:283 */
				#pwm-cells = < 0x3 >;          /* in zephyr/dts/arm/nordic/nrf91_peripherals.dtsi:284 */
			};

			/* node '/soc/peripheral@40000000/pwm@22000' defined in zephyr/dts/arm/nordic/nrf91_peripherals.dtsi:287 */
			pwm1: pwm@22000 {
				compatible = "nordic,nrf-pwm"; /* in zephyr/dts/arm/nordic/nrf91_peripherals.dtsi:288 */
				reg = < 0x22000 0x1000 >;      /* in zephyr/dts/arm/nordic/nrf91_peripherals.dtsi:289 */
				interrupts = < 0x22 0x1 >;     /* in zephyr/dts/arm/nordic/nrf91_peripherals.dtsi:290 */
				status = "disabled";           /* in zephyr/dts/arm/nordic/nrf91_peripherals.dtsi:291 */
				#pwm-cells = < 0x3 >;          /* in zephyr/dts/arm/nordic/nrf91_peripherals.dtsi:292 */
			};

			/* node '/soc/peripheral@40000000/pwm@23000' defined in zephyr/dts/arm/nordic/nrf91_peripherals.dtsi:295 */
			pwm2: pwm@23000 {
				compatible = "nordic,nrf-pwm"; /* in zephyr/dts/arm/nordic/nrf91_peripherals.dtsi:296 */
				reg = < 0x23000 0x1000 >;      /* in zephyr/dts/arm/nordic/nrf91_peripherals.dtsi:297 */
				interrupts = < 0x23 0x1 >;     /* in zephyr/dts/arm/nordic/nrf91_peripherals.dtsi:298 */
				status = "disabled";           /* in zephyr/dts/arm/nordic/nrf91_peripherals.dtsi:299 */
				#pwm-cells = < 0x3 >;          /* in zephyr/dts/arm/nordic/nrf91_peripherals.dtsi:300 */
			};

			/* node '/soc/peripheral@40000000/pwm@24000' defined in zephyr/dts/arm/nordic/nrf91_peripherals.dtsi:303 */
			pwm3: pwm@24000 {
				compatible = "nordic,nrf-pwm"; /* in zephyr/dts/arm/nordic/nrf91_peripherals.dtsi:304 */
				reg = < 0x24000 0x1000 >;      /* in zephyr/dts/arm/nordic/nrf91_peripherals.dtsi:305 */
				interrupts = < 0x24 0x1 >;     /* in zephyr/dts/arm/nordic/nrf91_peripherals.dtsi:306 */
				status = "disabled";           /* in zephyr/dts/arm/nordic/nrf91_peripherals.dtsi:307 */
				#pwm-cells = < 0x3 >;          /* in zephyr/dts/arm/nordic/nrf91_peripherals.dtsi:308 */
			};

			/* node '/soc/peripheral@40000000/gpio@842500' defined in zephyr/dts/arm/nordic/nrf91_peripherals.dtsi:311 */
			gpio0: gpio@842500 {
				compatible = "nordic,nrf-gpio"; /* in zephyr/dts/arm/nordic/nrf91_peripherals.dtsi:312 */
				gpio-controller;                /* in zephyr/dts/arm/nordic/nrf91_peripherals.dtsi:313 */
				reg = < 0x842500 0x300 >;       /* in zephyr/dts/arm/nordic/nrf91_peripherals.dtsi:314 */
				#gpio-cells = < 0x2 >;          /* in zephyr/dts/arm/nordic/nrf91_peripherals.dtsi:315 */
				port = < 0x0 >;                 /* in zephyr/dts/arm/nordic/nrf91_peripherals.dtsi:317 */
				gpiote-instance = < &gpiote >;  /* in zephyr/dts/arm/nordic/nrf91_peripherals.dtsi:318 */
				status = "okay";                /* in ../../Documents/DECT_2020_GIT/dect_shell/boards/nrf9151_connectkit/nrf9151_connectkit_nrf9151_common.dtsi:45 */
				phandle = < 0x6 >;              /* in ../../Documents/DECT_2020_GIT/dect_shell/boards/nrf9151_connectkit/nrf9151_connectkit_nrf9151_common.dtsi:22 */
			};

			/* node '/soc/peripheral@40000000/rtc@14000' defined in zephyr/dts/arm/nordic/nrf91_peripherals.dtsi:321 */
			rtc0: rtc@14000 {
				compatible = "nordic,nrf-rtc"; /* in zephyr/dts/arm/nordic/nrf91_peripherals.dtsi:322 */
				reg = < 0x14000 0x1000 >;      /* in zephyr/dts/arm/nordic/nrf91_peripherals.dtsi:323 */
				cc-num = < 0x4 >;              /* in zephyr/dts/arm/nordic/nrf91_peripherals.dtsi:324 */
				interrupts = < 0x14 0x1 >;     /* in zephyr/dts/arm/nordic/nrf91_peripherals.dtsi:325 */
				status = "disabled";           /* in zephyr/dts/arm/nordic/nrf91_peripherals.dtsi:326 */
				clock-frequency = < 0x8000 >;  /* in zephyr/dts/arm/nordic/nrf91_peripherals.dtsi:327 */
				prescaler = < 0x1 >;           /* in zephyr/dts/arm/nordic/nrf91_peripherals.dtsi:328 */
			};

			/* node '/soc/peripheral@40000000/rtc@15000' defined in zephyr/dts/arm/nordic/nrf91_peripherals.dtsi:331 */
			rtc1: rtc@15000 {
				compatible = "nordic,nrf-rtc"; /* in zephyr/dts/arm/nordic/nrf91_peripherals.dtsi:332 */
				reg = < 0x15000 0x1000 >;      /* in zephyr/dts/arm/nordic/nrf91_peripherals.dtsi:333 */
				cc-num = < 0x4 >;              /* in zephyr/dts/arm/nordic/nrf91_peripherals.dtsi:334 */
				interrupts = < 0x15 0x1 >;     /* in zephyr/dts/arm/nordic/nrf91_peripherals.dtsi:335 */
				status = "disabled";           /* in zephyr/dts/arm/nordic/nrf91_peripherals.dtsi:336 */
				clock-frequency = < 0x8000 >;  /* in zephyr/dts/arm/nordic/nrf91_peripherals.dtsi:337 */
				prescaler = < 0x1 >;           /* in zephyr/dts/arm/nordic/nrf91_peripherals.dtsi:338 */
			};

			/* node '/soc/peripheral@40000000/clock@5000' defined in zephyr/dts/arm/nordic/nrf91_peripherals.dtsi:341 */
			clock: clock@5000 {
				compatible = "nordic,nrf-clock"; /* in zephyr/dts/arm/nordic/nrf91_peripherals.dtsi:342 */
				reg = < 0x5000 0x1000 >;         /* in zephyr/dts/arm/nordic/nrf91_peripherals.dtsi:343 */
				interrupts = < 0x5 0x1 >;        /* in zephyr/dts/arm/nordic/nrf91_peripherals.dtsi:344 */
				status = "okay";                 /* in zephyr/dts/arm/nordic/nrf91_peripherals.dtsi:345 */
			};

			/* node '/soc/peripheral@40000000/power@5000' defined in zephyr/dts/arm/nordic/nrf91_peripherals.dtsi:348 */
			power: power@5000 {
				compatible = "nordic,nrf-power"; /* in zephyr/dts/arm/nordic/nrf91_peripherals.dtsi:349 */
				reg = < 0x5000 0x1000 >;         /* in zephyr/dts/arm/nordic/nrf91_peripherals.dtsi:350 */
				ranges = < 0x0 0x5000 0x1000 >;  /* in zephyr/dts/arm/nordic/nrf91_peripherals.dtsi:351 */
				interrupts = < 0x5 0x1 >;        /* in zephyr/dts/arm/nordic/nrf91_peripherals.dtsi:352 */
				status = "okay";                 /* in zephyr/dts/arm/nordic/nrf91_peripherals.dtsi:353 */
				#address-cells = < 0x1 >;        /* in zephyr/dts/arm/nordic/nrf91_peripherals.dtsi:354 */
				#size-cells = < 0x1 >;           /* in zephyr/dts/arm/nordic/nrf91_peripherals.dtsi:355 */

				/* node '/soc/peripheral@40000000/power@5000/gpregret1@51c' defined in zephyr/dts/arm/nordic/nrf91_peripherals.dtsi:357 */
				gpregret1: gpregret1@51c {
					#address-cells = < 0x1 >;           /* in zephyr/dts/arm/nordic/nrf91_peripherals.dtsi:358 */
					#size-cells = < 0x1 >;              /* in zephyr/dts/arm/nordic/nrf91_peripherals.dtsi:359 */
					compatible = "nordic,nrf-gpregret"; /* in zephyr/dts/arm/nordic/nrf91_peripherals.dtsi:360 */
					reg = < 0x51c 0x1 >;                /* in zephyr/dts/arm/nordic/nrf91_peripherals.dtsi:361 */
					status = "okay";                    /* in zephyr/dts/arm/nordic/nrf91_peripherals.dtsi:362 */
				};

				/* node '/soc/peripheral@40000000/power@5000/gpregret2@520' defined in zephyr/dts/arm/nordic/nrf91_peripherals.dtsi:365 */
				gpregret2: gpregret2@520 {
					#address-cells = < 0x1 >;           /* in zephyr/dts/arm/nordic/nrf91_peripherals.dtsi:366 */
					#size-cells = < 0x1 >;              /* in zephyr/dts/arm/nordic/nrf91_peripherals.dtsi:367 */
					compatible = "nordic,nrf-gpregret"; /* in zephyr/dts/arm/nordic/nrf91_peripherals.dtsi:368 */
					reg = < 0x520 0x1 >;                /* in zephyr/dts/arm/nordic/nrf91_peripherals.dtsi:369 */
					status = "okay";                    /* in zephyr/dts/arm/nordic/nrf91_peripherals.dtsi:370 */
				};
			};

			/* node '/soc/peripheral@40000000/watchdog@18000' defined in zephyr/dts/arm/nordic/nrf91_peripherals.dtsi:374 */
			wdt: wdt0: watchdog@18000 {
				compatible = "nordic,nrf-wdt"; /* in zephyr/dts/arm/nordic/nrf91_peripherals.dtsi:375 */
				reg = < 0x18000 0x1000 >;      /* in zephyr/dts/arm/nordic/nrf91_peripherals.dtsi:376 */
				interrupts = < 0x18 0x1 >;     /* in zephyr/dts/arm/nordic/nrf91_peripherals.dtsi:377 */
				status = "okay";               /* in zephyr/dts/arm/nordic/nrf91_peripherals.dtsi:378 */
			};

			/* node '/soc/peripheral@40000000/timer@f000' defined in zephyr/dts/arm/nordic/nrf91_peripherals.dtsi:381 */
			timer0: timer@f000 {
				compatible = "nordic,nrf-timer"; /* in zephyr/dts/arm/nordic/nrf91_peripherals.dtsi:382 */
				status = "disabled";             /* in zephyr/dts/arm/nordic/nrf91_peripherals.dtsi:383 */
				reg = < 0xf000 0x1000 >;         /* in zephyr/dts/arm/nordic/nrf91_peripherals.dtsi:384 */
				cc-num = < 0x6 >;                /* in zephyr/dts/arm/nordic/nrf91_peripherals.dtsi:385 */
				max-bit-width = < 0x20 >;        /* in zephyr/dts/arm/nordic/nrf91_peripherals.dtsi:386 */
				interrupts = < 0xf 0x1 >;        /* in zephyr/dts/arm/nordic/nrf91_peripherals.dtsi:387 */
				prescaler = < 0x0 >;             /* in zephyr/dts/arm/nordic/nrf91_peripherals.dtsi:388 */
			};

			/* node '/soc/peripheral@40000000/timer@10000' defined in zephyr/dts/arm/nordic/nrf91_peripherals.dtsi:391 */
			timer1: timer@10000 {
				compatible = "nordic,nrf-timer"; /* in zephyr/dts/arm/nordic/nrf91_peripherals.dtsi:392 */
				status = "disabled";             /* in zephyr/dts/arm/nordic/nrf91_peripherals.dtsi:393 */
				reg = < 0x10000 0x1000 >;        /* in zephyr/dts/arm/nordic/nrf91_peripherals.dtsi:394 */
				cc-num = < 0x6 >;                /* in zephyr/dts/arm/nordic/nrf91_peripherals.dtsi:395 */
				max-bit-width = < 0x20 >;        /* in zephyr/dts/arm/nordic/nrf91_peripherals.dtsi:396 */
				interrupts = < 0x10 0x1 >;       /* in zephyr/dts/arm/nordic/nrf91_peripherals.dtsi:397 */
				prescaler = < 0x0 >;             /* in zephyr/dts/arm/nordic/nrf91_peripherals.dtsi:398 */
				phandle = < 0x5 >;               /* in zephyr/dts/vendor/nordic/nrf_common.dtsi:42 */
			};

			/* node '/soc/peripheral@40000000/timer@11000' defined in zephyr/dts/arm/nordic/nrf91_peripherals.dtsi:401 */
			timer2: timer@11000 {
				compatible = "nordic,nrf-timer"; /* in zephyr/dts/arm/nordic/nrf91_peripherals.dtsi:402 */
				status = "disabled";             /* in zephyr/dts/arm/nordic/nrf91_peripherals.dtsi:403 */
				reg = < 0x11000 0x1000 >;        /* in zephyr/dts/arm/nordic/nrf91_peripherals.dtsi:404 */
				cc-num = < 0x6 >;                /* in zephyr/dts/arm/nordic/nrf91_peripherals.dtsi:405 */
				max-bit-width = < 0x20 >;        /* in zephyr/dts/arm/nordic/nrf91_peripherals.dtsi:406 */
				interrupts = < 0x11 0x1 >;       /* in zephyr/dts/arm/nordic/nrf91_peripherals.dtsi:407 */
				prescaler = < 0x0 >;             /* in zephyr/dts/arm/nordic/nrf91_peripherals.dtsi:408 */
			};
		};

		/* node '/soc/gpiote@40031000' defined in zephyr/dts/arm/nordic/nrf91_ns.dtsi:57 */
		gpiote: gpiote1: gpiote@40031000 {
			compatible = "nordic,nrf-gpiote"; /* in zephyr/dts/arm/nordic/nrf91_ns.dtsi:58 */
			reg = < 0x40031000 0x1000 >;      /* in zephyr/dts/arm/nordic/nrf91_ns.dtsi:59 */
			interrupts = < 0x31 0x5 >;        /* in zephyr/dts/arm/nordic/nrf91_ns.dtsi:60 */
			instance = < 0x1 >;               /* in zephyr/dts/arm/nordic/nrf91_ns.dtsi:62 */
			status = "okay";                  /* in ../../Documents/DECT_2020_GIT/dect_shell/boards/nrf9151_connectkit/nrf9151_connectkit_nrf9151_common.dtsi:41 */
			phandle = < 0x4 >;                /* in zephyr/dts/arm/nordic/nrf91_peripherals.dtsi:318 */
		};
	};

	/* node '/pin-controller' defined in zephyr/dts/vendor/nordic/nrf_common.dtsi:26 */
	pinctrl: pin-controller {
		compatible = "nordic,nrf-pinctrl"; /* in zephyr/dts/vendor/nordic/nrf_common.dtsi:31 */

		/* node '/pin-controller/uart0_default' defined in ../../Documents/DECT_2020_GIT/dect_shell/boards/nrf9151_connectkit/nrf9151_connectkit_nrf9151_common-pinctrl.dtsi:7 */
		uart0_default: uart0_default {
			phandle = < 0x2 >; /* in ../../Documents/DECT_2020_GIT/dect_shell/boards/nrf9151_connectkit/nrf9151_connectkit_nrf9151_common.dtsi:51 */

			/* node '/pin-controller/uart0_default/group1' defined in ../../Documents/DECT_2020_GIT/dect_shell/boards/nrf9151_connectkit/nrf9151_connectkit_nrf9151_common-pinctrl.dtsi:8 */
			group1 {
				psels = < 0xb >; /* in ../../Documents/DECT_2020_GIT/dect_shell/boards/nrf9151_connectkit/nrf9151_connectkit_nrf9151_common-pinctrl.dtsi:9 */
			};

			/* node '/pin-controller/uart0_default/group2' defined in ../../Documents/DECT_2020_GIT/dect_shell/boards/nrf9151_connectkit/nrf9151_connectkit_nrf9151_common-pinctrl.dtsi:11 */
			group2 {
				psels = < 0x100000c >; /* in ../../Documents/DECT_2020_GIT/dect_shell/boards/nrf9151_connectkit/nrf9151_connectkit_nrf9151_common-pinctrl.dtsi:12 */
				bias-pull-up;          /* in ../../Documents/DECT_2020_GIT/dect_shell/boards/nrf9151_connectkit/nrf9151_connectkit_nrf9151_common-pinctrl.dtsi:13 */
			};
		};

		/* node '/pin-controller/uart0_sleep' defined in ../../Documents/DECT_2020_GIT/dect_shell/boards/nrf9151_connectkit/nrf9151_connectkit_nrf9151_common-pinctrl.dtsi:17 */
		uart0_sleep: uart0_sleep {
			phandle = < 0x3 >; /* in ../../Documents/DECT_2020_GIT/dect_shell/boards/nrf9151_connectkit/nrf9151_connectkit_nrf9151_common.dtsi:52 */

			/* node '/pin-controller/uart0_sleep/group1' defined in ../../Documents/DECT_2020_GIT/dect_shell/boards/nrf9151_connectkit/nrf9151_connectkit_nrf9151_common-pinctrl.dtsi:18 */
			group1 {
				psels = < 0xb >,
				        < 0x100000c >; /* in ../../Documents/DECT_2020_GIT/dect_shell/boards/nrf9151_connectkit/nrf9151_connectkit_nrf9151_common-pinctrl.dtsi:19 */
				low-power-enable;      /* in ../../Documents/DECT_2020_GIT/dect_shell/boards/nrf9151_connectkit/nrf9151_connectkit_nrf9151_common-pinctrl.dtsi:21 */
			};
		};
	};

	/* node '/entropy_bt_hci' defined in zephyr/dts/vendor/nordic/nrf_common.dtsi:34 */
	rng_hci: entropy_bt_hci {
		compatible = "zephyr,bt-hci-entropy"; /* in zephyr/dts/vendor/nordic/nrf_common.dtsi:35 */
		status = "disabled";                  /* in zephyr/dts/vendor/nordic/nrf_common.dtsi:36 */
	};

	/* node '/sw-pwm' defined in zephyr/dts/vendor/nordic/nrf_common.dtsi:39 */
	sw_pwm: sw-pwm {
		compatible = "nordic,nrf-sw-pwm"; /* in zephyr/dts/vendor/nordic/nrf_common.dtsi:40 */
		status = "disabled";              /* in zephyr/dts/vendor/nordic/nrf_common.dtsi:41 */
		generator = < &timer1 >;          /* in zephyr/dts/vendor/nordic/nrf_common.dtsi:42 */
		clock-prescaler = < 0x0 >;        /* in zephyr/dts/vendor/nordic/nrf_common.dtsi:43 */
		#pwm-cells = < 0x3 >;             /* in zephyr/dts/vendor/nordic/nrf_common.dtsi:44 */
	};

	/* node '/cpus' defined in zephyr/dts/arm/nordic/nrf91_ns.dtsi:12 */
	cpus {
		#address-cells = < 0x1 >; /* in zephyr/dts/arm/nordic/nrf91_ns.dtsi:13 */
		#size-cells = < 0x0 >;    /* in zephyr/dts/arm/nordic/nrf91_ns.dtsi:14 */

		/* node '/cpus/cpu@0' defined in zephyr/dts/arm/nordic/nrf91_ns.dtsi:16 */
		cpu@0 {
			device_type = "cpu";            /* in zephyr/dts/arm/nordic/nrf91_ns.dtsi:17 */
			compatible = "arm,cortex-m33f"; /* in zephyr/dts/arm/nordic/nrf91_ns.dtsi:18 */
			reg = < 0x0 >;                  /* in zephyr/dts/arm/nordic/nrf91_ns.dtsi:19 */
			#address-cells = < 0x1 >;       /* in zephyr/dts/arm/nordic/nrf91_ns.dtsi:20 */
			#size-cells = < 0x1 >;          /* in zephyr/dts/arm/nordic/nrf91_ns.dtsi:21 */

			/* node '/cpus/cpu@0/mpu@e000ed90' defined in zephyr/dts/arm/nordic/nrf91_ns.dtsi:23 */
			mpu: mpu@e000ed90 {
				compatible = "arm,armv8m-mpu"; /* in zephyr/dts/arm/nordic/nrf91_ns.dtsi:24 */
				reg = < 0xe000ed90 0x40 >;     /* in zephyr/dts/arm/nordic/nrf91_ns.dtsi:25 */
			};
		};
	};

	/* node '/psa-rng' defined in zephyr/dts/arm/nordic/nrf91_ns.dtsi:66 */
	psa_rng: psa-rng {
		compatible = "zephyr,psa-crypto-rng"; /* in zephyr/dts/arm/nordic/nrf91_ns.dtsi:67 */
		status = "okay";                      /* in zephyr/dts/arm/nordic/nrf91_ns.dtsi:68 */
	};

	/* node '/buttons' defined in ../../Documents/DECT_2020_GIT/dect_shell/boards/nrf9151_connectkit/nrf9151_connectkit_nrf9151_common.dtsi:19 */
	buttons {
		compatible = "gpio-keys"; /* in ../../Documents/DECT_2020_GIT/dect_shell/boards/nrf9151_connectkit/nrf9151_connectkit_nrf9151_common.dtsi:20 */

		/* node '/buttons/button_0' defined in ../../Documents/DECT_2020_GIT/dect_shell/boards/nrf9151_connectkit/nrf9151_connectkit_nrf9151_common.dtsi:21 */
		button0: button_0 {
			gpios = < &gpio0 0x19 0x11 >; /* in ../../Documents/DECT_2020_GIT/dect_shell/boards/nrf9151_connectkit/nrf9151_connectkit_nrf9151_common.dtsi:22 */
			label = "Push button 1";      /* in ../../Documents/DECT_2020_GIT/dect_shell/boards/nrf9151_connectkit/nrf9151_connectkit_nrf9151_common.dtsi:23 */
			zephyr,code = < 0xb >;        /* in ../../Documents/DECT_2020_GIT/dect_shell/boards/nrf9151_connectkit/nrf9151_connectkit_nrf9151_common.dtsi:24 */
		};
	};
};
